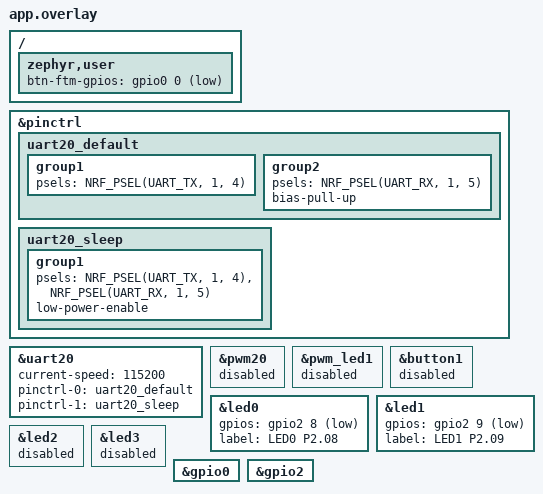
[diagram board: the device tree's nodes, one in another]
/*
 * factory — pin map aligned with demo / MCUBoot (TY board).
 *
 * UART20 console: TX=P1.04  RX=P1.05  @ 115200  (must match bootloader)
 * LED0=P2.08  LED1=P2.09  (GPIO_ACTIVE_LOW)
 * FTM 按键：P0.00 ACTIVE_LOW + PULL_UP（BTN_PERMISSION_FTM）
 */

#include <zephyr/dt-bindings/gpio/gpio.h>
#include <zephyr/dt-bindings/pinctrl/nrf-pinctrl.h>

&pinctrl {
	uart20_default: uart20_default {
		group1 {
			psels = <NRF_PSEL(UART_TX, 1, 4)>;
		};
		group2 {
			psels = <NRF_PSEL(UART_RX, 1, 5)>;
			bias-pull-up;
		};
	};

	uart20_sleep: uart20_sleep {
		group1 {
			psels = <NRF_PSEL(UART_TX, 1, 4)>,
				<NRF_PSEL(UART_RX, 1, 5)>;
			low-power-enable;
		};
	};
};

&uart20 {
	status = "okay";
	current-speed = <115200>;
	pinctrl-0 = <&uart20_default>;
	pinctrl-1 = <&uart20_sleep>;
	pinctrl-names = "default", "sleep";
};

&pwm20 {
	status = "disabled";
};

&pwm_led1 {
	status = "disabled";
};

&button1 {
	status = "disabled";
};

&led0 {
	gpios = <&gpio2 8 GPIO_ACTIVE_LOW>;
	label = "LED0 P2.08";
};

&led1 {
	gpios = <&gpio2 9 GPIO_ACTIVE_LOW>;
	label = "LED1 P2.09";
};

&led2 {
	status = "disabled";
};

&led3 {
	status = "disabled";
};

&gpio0 {
	status = "okay";
};

&gpio2 {
	status = "okay";
};

/ {
	zephyr,user {
		btn-ftm-gpios = <&gpio0 0 (GPIO_ACTIVE_LOW | GPIO_PULL_UP)>;
	};
};
